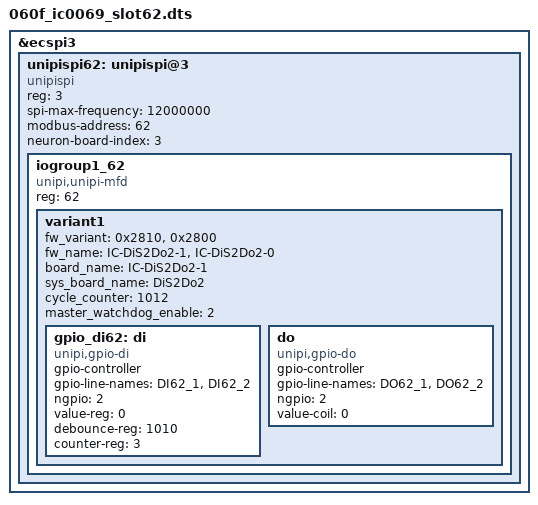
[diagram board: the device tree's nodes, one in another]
/dts-v1/;


/plugin/;

/ {
	fragment@1 {
		
		target = <&ecspi3>;
		__overlay__ {
			status = "okay";
			#address-cells = <1>;
			#size-cells = <0>;

			unipispi62: unipispi@3 {
				compatible = "unipispi";
				reg = <3>;
				status = "okay";
				spi-max-frequency = <12000000>;
				modbus-address = <62>;
				neuron-board-index = <3>;
			};
		};

	};

	fragment@2 {
		target = <&unipispi62>;
		__overlay__ {
			#address-cells = <1>;
			#size-cells = <0>;

			iogroup1_62 {
				reg = <62>;
				compatible = "unipi,unipi-mfd", "iogroup";
				variant1 { 
					fw_variant = <0x2810>, <0x2800>;
					fw_name = "IC-DiS2Do2-1" , "IC-DiS2Do2-0";
					board_name = "IC-DiS2Do2-1";
					sys_board_name = "DiS2Do2";
					cycle_counter = <1012>;
					master_watchdog_enable = <2>;

					gpio_di62:di {
						compatible = "unipi,gpio-di";
						gpio-controller;
						#gpio-cells = <2>;
						gpio-line-names = "DI62_1", "DI62_2";
						ngpio = <2>;
						value-reg = <0>;
						debounce-reg = <1010>;
						counter-reg = <3>;
					};
					do {
						compatible = "unipi,gpio-do";
						gpio-controller;
						#gpio-cells = <2>;
						gpio-line-names = "DO62_1", "DO62_2";
						ngpio = <2>;
						value-coil = <0>;
					};
				};
			};
		};
	};
};
